# STM32L15x register map
File version: 1.0
Registers are 32-bit, read-write, reset 0x0 unless marked. A register's access mark holds for its fields unless they carry their own. Offsets are from the block's base; lines under a group give offsets from that group; [hi:lo] are bit positions; {n}, {i} and the like mark numbered series; 'fields as' and 'values as' point back to an identical list; <NAME> marks a mode.

## Memory map
0x40000000 TIM2 size 0x400
0x40000400 TIM3 size 0x400
0x40000800 TIM4 size 0x400
0x40001000 TIM6 size 0x400
0x40001400 TIM7 size 0x400
0x40002400 LCD size 0x400 — LCD controller
0x40002800 RTC size 0x400 — Real-time clock
0x40002C00 WWDG size 0x400 — Window watchdog
0x40003000 IWDG size 0x400 — Independent watchdog
0x40003800 SPI2 size 0x400
0x40004400 USART2 size 0x400
0x40004800 USART3 size 0x400
0x40005400 I2C1 size 0x400
0x40005800 I2C2 size 0x400 — Inter-integrated circuit
0x40005C00 USB size 0x400
0x40007000 PWR size 0x400 — Power control
0x40007400 DAC size 0x400 — Digital-to-analog converter
0x40007C00 COMP size 0x400 — Comparators
0x40007C04 RI size 0x400 — Routing interface (RI)
0x40010000 SYSCFG size 0x400 — System configuration controller
0x40010400 EXTI size 0x400 — External interrupt/event controller
0x40010800 TIM9 size 0x400
0x40010C00 TIM10 size 0x400
0x40011000 TIM11 size 0x400 — General-purpose timers
0x40012400 ADC size 0x400 — Analog-to-digital converter
0x40013000 SPI1 size 0x400 — Serial peripheral interface
0x40013800 USART1 size 0x400 — Universal synchronous asynchronous receiver
0x40020000 GPIOA size 0x400 — General-purpose I/Os
0x40020400 GPIOB size 0x400
0x40020800 GPIOC size 0x400
0x40020C00 GPIOD size 0x400
0x40021000 GPIOE size 0x400
0x40021400 GPIOF size 0x400
0x40023000 CRC size 0x400 — CRC calculation unit
0x40023800 RCC size 0x400 — Reset and clock control
0x40023C00 Flash size 0x400
0x40026000 DMA size 0x400 — DMA controller
0xE000E004 NVIC size 0x11FC — Nested vectored interrupt controller
0xE0042000 DBG size 0x400 — Debug support

## NVIC — Nested vectored interrupt controller
Base 0xE000E004
0x00 NVIC ro reset 0x1
  [4:0] INTLINESNUM
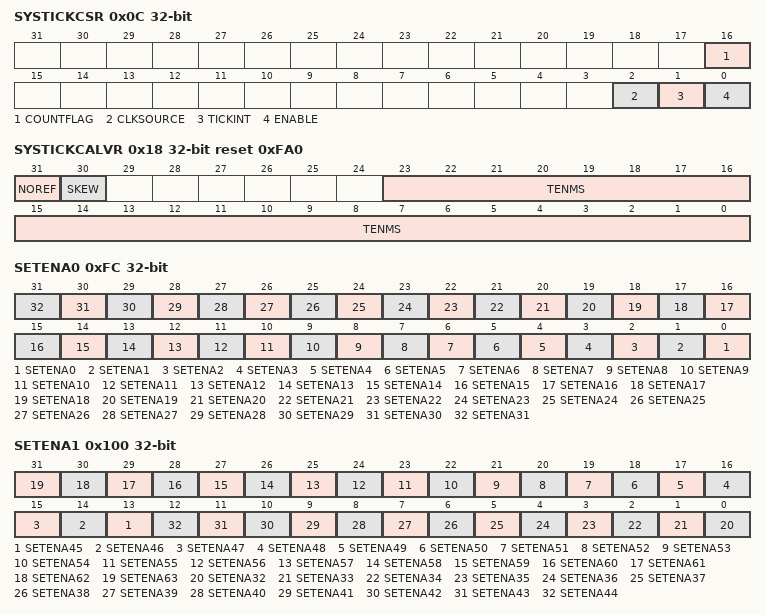
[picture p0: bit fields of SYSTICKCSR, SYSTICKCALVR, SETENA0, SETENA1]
0x0C SYSTICKCSR access per field
  [16] COUNTFLAG ro, [2] CLKSOURCE rw, [1] TICKINT rw, [0] ENABLE rw
0x10 SYSTICKRVR
  [23:0] RELOAD
0x14 SYSTICKCVR
  [23:0] CURRENT
0x18 SYSTICKCALVR ro reset 0xFA0
  [31] NOREF, [30] SKEW, [23:0] TENMS
0xFC SETENA0
  [n] SETENA{n} (n=0..31)
0x100 SETENA1 access per field
  [n-32] SETENA{n} ro (n=45..63), [n-32] SETENA{n} rw (n=32..44)
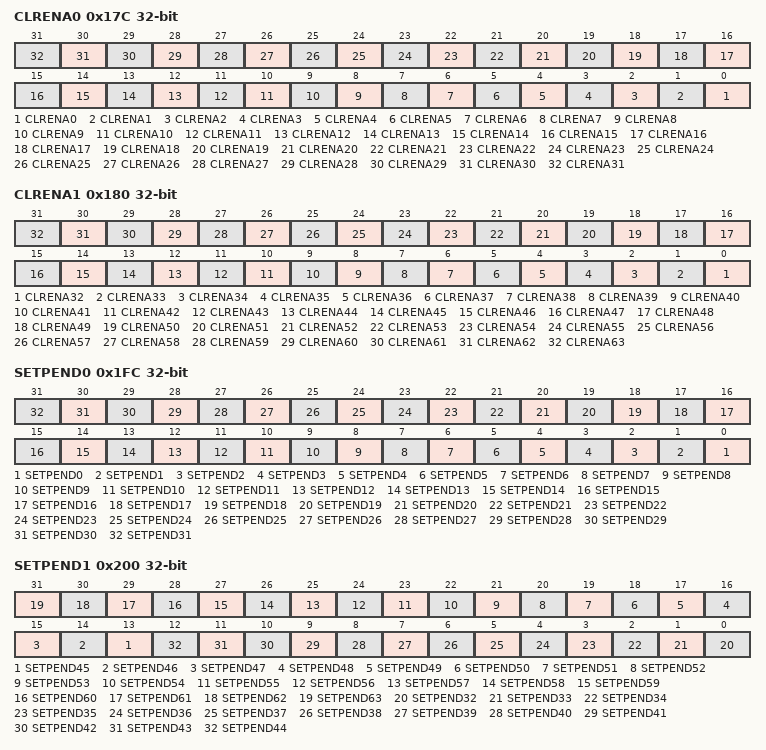
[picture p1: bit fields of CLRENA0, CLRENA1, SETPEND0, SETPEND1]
0x17C CLRENA0 ro
  [n] CLRENA{n} (n=0..31)
0x180 CLRENA1 ro
  [n-32] CLRENA{n} (n=32..63)
0x1FC SETPEND0
  [n] SETPEND{n} (n=0..31)
0x200 SETPEND1 access per field
  [n-32] SETPEND{n} ro (n=45..63), [n-32] SETPEND{n} rw (n=32..44)
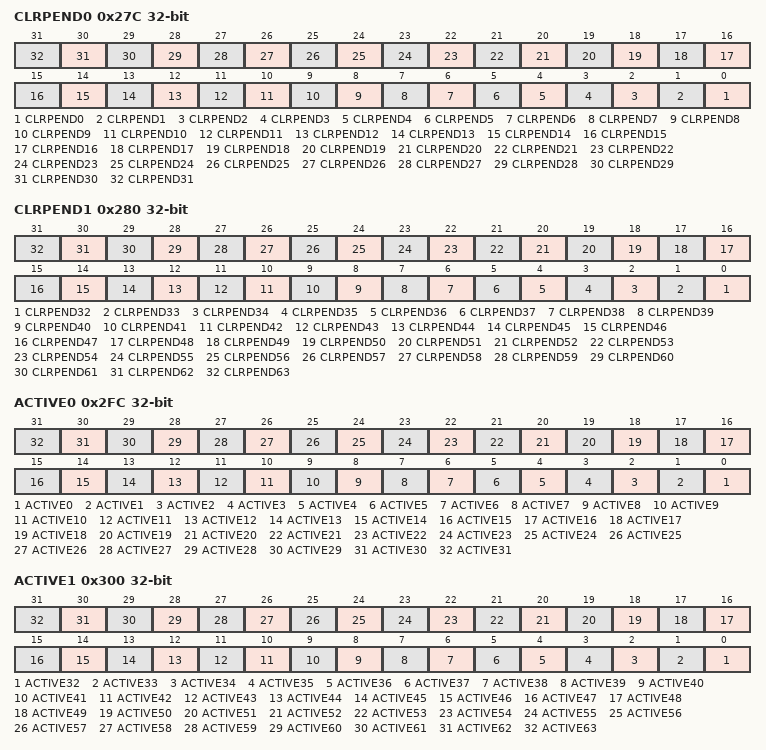
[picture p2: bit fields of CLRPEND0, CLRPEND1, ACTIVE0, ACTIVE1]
0x27C CLRPEND0 ro
  [n] CLRPEND{n} (n=0..31)
0x280 CLRPEND1 ro
  [n-32] CLRPEND{n} (n=32..63)
0x2FC ACTIVE0 ro
  [n] ACTIVE{n} (n=0..31)
0x300 ACTIVE1 ro
  [n-32] ACTIVE{n} (n=32..63)
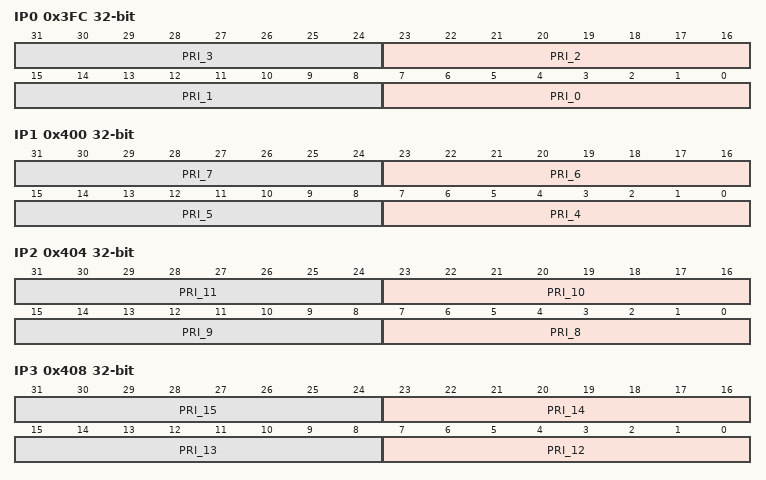
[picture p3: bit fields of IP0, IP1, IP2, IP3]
0x3FC IP0 ro
  [8n+7:8n] PRI_{n} (n=0..3)
0x400 IP1 ro
  [8n-25:8n-32] PRI_{n} (n=4..7)
0x404 IP2 ro
  [8n-57:8n-64] PRI_{n} (n=8..11)
0x408 IP3 ro
  [8n-89:8n-96] PRI_{n} (n=12..15)
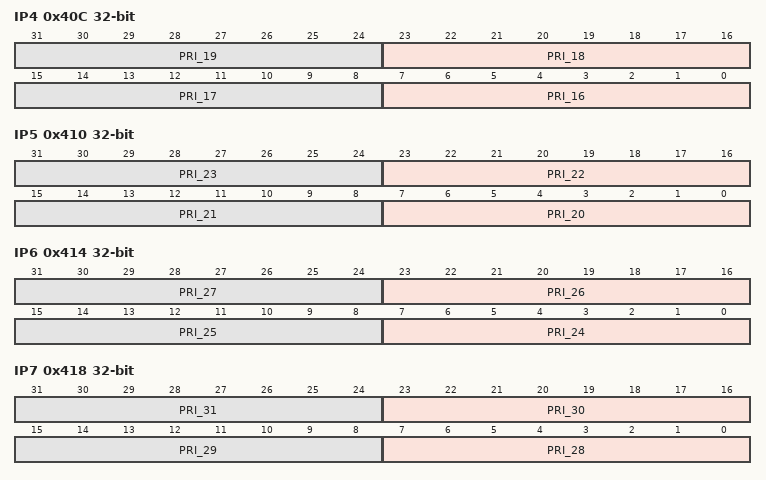
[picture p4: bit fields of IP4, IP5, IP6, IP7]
0x40C IP4 ro
  [8n-121:8n-128] PRI_{n} (n=16..19)
0x410 IP5 ro
  [8n-153:8n-160] PRI_{n} (n=20..23)
0x414 IP6 ro
  [8n-185:8n-192] PRI_{n} (n=24..27)
0x418 IP7 ro
  [8n-217:8n-224] PRI_{n} (n=28..31)
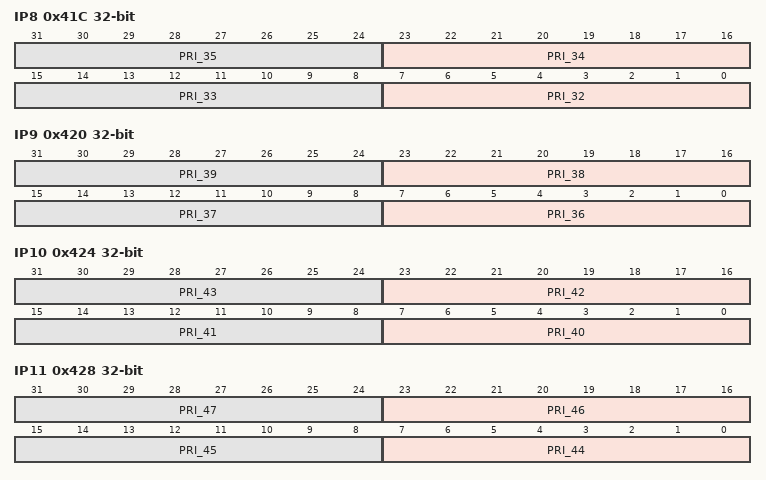
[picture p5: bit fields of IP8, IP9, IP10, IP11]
0x41C IP8 ro
  [8n-249:8n-256] PRI_{n} (n=32..35)
0x420 IP9 ro
  [8n-281:8n-288] PRI_{n} (n=36..39)
0x424 IP10 ro
  [8n-313:8n-320] PRI_{n} (n=40..43)
0x428 IP11 ro
  [8n-345:8n-352] PRI_{n} (n=44..47)
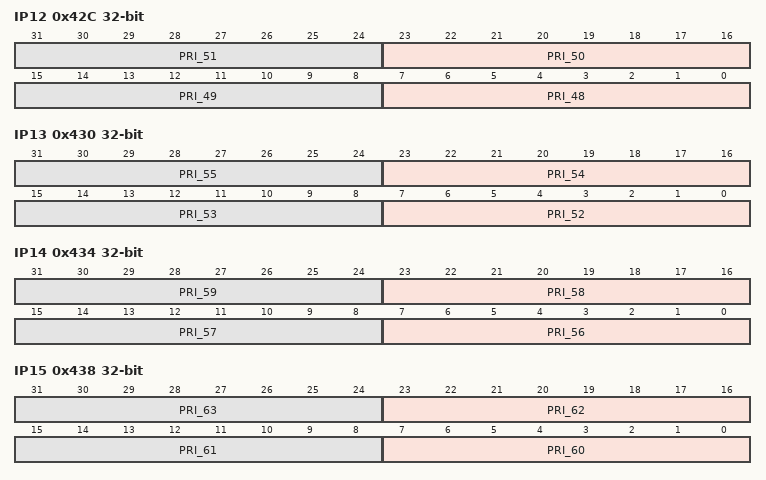
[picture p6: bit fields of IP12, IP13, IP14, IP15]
0x42C IP12 ro
  [8n-377:8n-384] PRI_{n} (n=48..51)
0x430 IP13 ro
  [8n-409:8n-416] PRI_{n} (n=52..55)
0x434 IP14 ro
  [8n-441:8n-448] PRI_{n} (n=56..59)
0x438 IP15 ro
  [8n-473:8n-480] PRI_{n} (n=60..63)
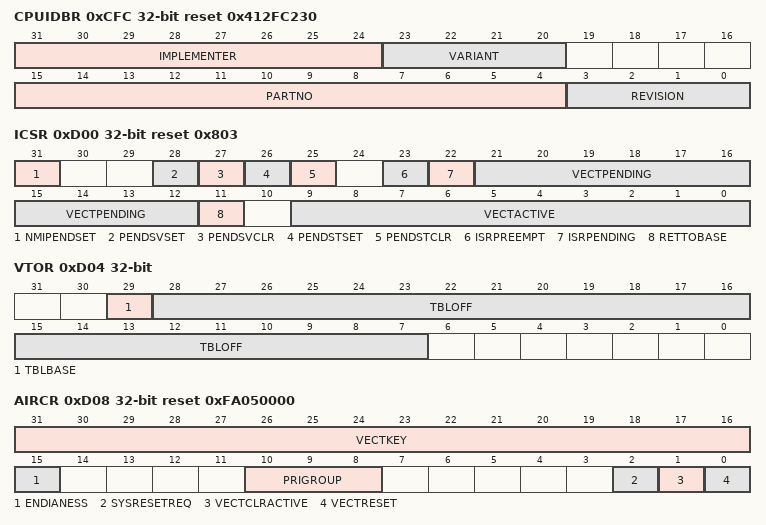
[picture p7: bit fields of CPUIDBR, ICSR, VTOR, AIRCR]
0xCFC CPUIDBR ro reset 0x412FC230
  [31:24] IMPLEMENTER, [23:20] VARIANT, [15:4] PARTNO, [3:0] REVISION
0xD00 ICSR access per field reset 0x803
  [31] NMIPENDSET ro, [28] PENDSVSET rw, [27] PENDSVCLR ro, [26] PENDSTSET ro, [25] PENDSTCLR ro, [23] ISRPREEMPT ro, [22] ISRPENDING ro, [21:12] VECTPENDING ro, [11] RETTOBASE ro, [9:0] VECTACTIVE ro
0xD04 VTOR
  [29] TBLBASE, [28:7] TBLOFF
0xD08 AIRCR ro reset 0xFA050000
  [31:16] VECTKEY, [15] ENDIANESS, [10:8] PRIGROUP, [2] SYSRESETREQ, [1] VECTCLRACTIVE, [0] VECTRESET
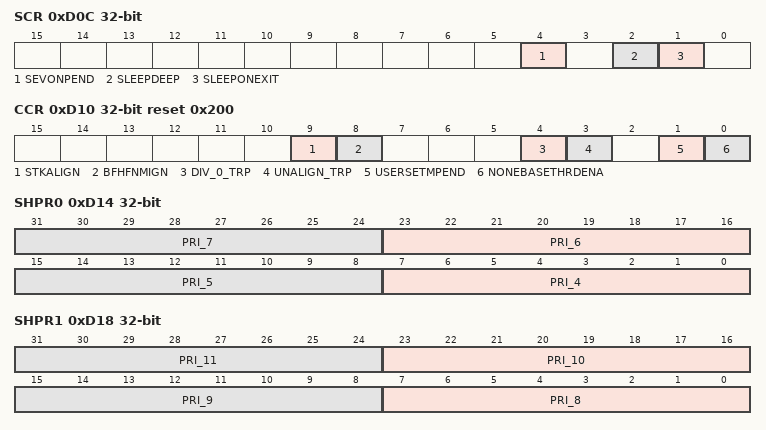
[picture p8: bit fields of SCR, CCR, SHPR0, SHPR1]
0xD0C SCR
  [4] SEVONPEND, [2] SLEEPDEEP, [1] SLEEPONEXIT
0xD10 CCR reset 0x200
  [9] STKALIGN, [8] BFHFNMIGN, [4] DIV_0_TRP, [3] UNALIGN_TRP, [1] USERSETMPEND, [0] NONEBASETHRDENA
0xD14 SHPR0 ro
  [8n-25:8n-32] PRI_{n} (n=4..7)
0xD18 SHPR1 ro
  [8n-57:8n-64] PRI_{n} (n=8..11)
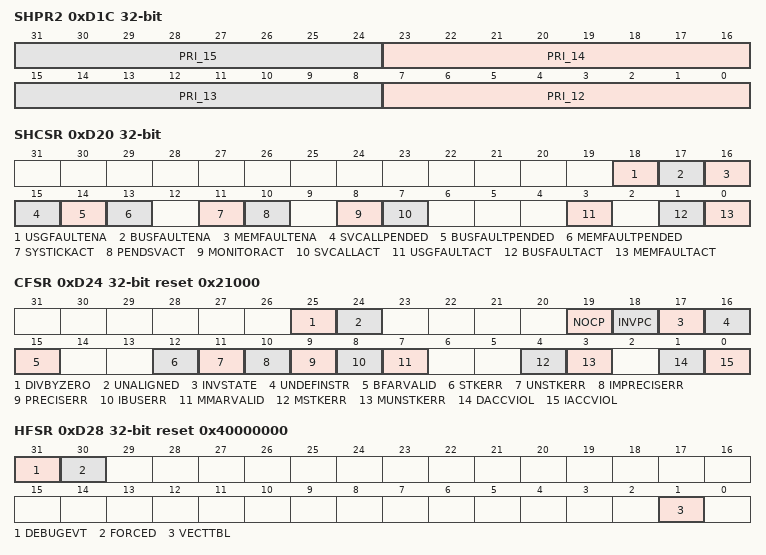
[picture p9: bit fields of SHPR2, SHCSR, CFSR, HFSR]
0xD1C SHPR2 ro
  [8n-89:8n-96] PRI_{n} (n=12..15)
0xD20 SHCSR
  [18] USGFAULTENA, [17] BUSFAULTENA, [16] MEMFAULTENA, [15] SVCALLPENDED, [14] BUSFAULTPENDED, [13] MEMFAULTPENDED, [11] SYSTICKACT, [10] PENDSVACT, [8] MONITORACT, [7] SVCALLACT, [3] USGFAULTACT, [1] BUSFAULTACT, [0] MEMFAULTACT
0xD24 CFSR ro reset 0x21000
  [25] DIVBYZERO, [24] UNALIGNED, [19] NOCP, [18] INVPC, [17] INVSTATE, [16] UNDEFINSTR, [15] BFARVALID, [12] STKERR, [11] UNSTKERR, [10] IMPRECISERR, [9] PRECISERR, [8] IBUSERR, [7] MMARVALID, [4] MSTKERR, [3] MUNSTKERR, [1] DACCVIOL, [0] IACCVIOL
0xD28 HFSR ro reset 0x40000000
  [31] DEBUGEVT, [30] FORCED, [1] VECTTBL
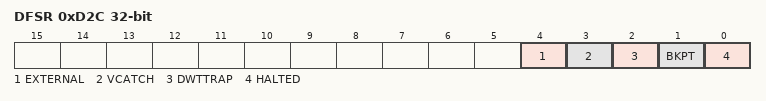
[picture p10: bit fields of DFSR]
0xD2C DFSR ro
  [4] EXTERNAL, [3] VCATCH, [2] DWTTRAP, [1] BKPT, [0] HALTED
0xD30 MMFAR reset 0xFFFFFFF8
0xD34 BFAR reset 0xFFFFFFF8
0xEFC STIR ro
  [8:0] INTID
